AUTOSAR XML (schema 4-0-3)
standard types defined: UInt32, UInt8
package /AUTOSAR_Platform/DataConstrs
  range DC_UInt8: raw 0..255
package /PATAC/Facility/DataTypes/Implementation
  unit NoUnit: factor-si-to-unit=1, offset-si-to-unit=0
package /PATAC/MSM/ComponentTypes
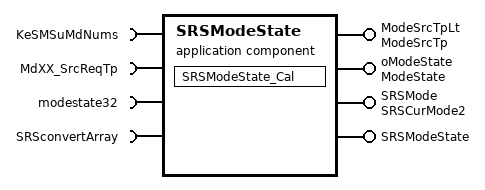
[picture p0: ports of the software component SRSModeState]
  application sw component type SRSModeState
    4 x provide port:
      ModeSrcTpLt: nonqueued-sender-com-spec{data-element=ModeSrcTp/Val, init-value=0}, provided-interface=ModeSrcTp
      oModeState: nonqueued-sender-com-spec=data-element=ModeState/Val, provided-interface=ModeState
      SRSMode: nonqueued-sender-com-spec{data-element=SRSCurMode2/Val, init-value=0}, provided-interface=SRSCurMode2
      SRSModeState: server-com-spec{operation=Cal, queue-length=1}, provided-interface=SRSModeState
    4 x require port:
      KeSMSuMdNums: parameter-require-com-spec{init-value=26, parameter=KeSMSuMdNums/Val}, required-interface=KeSMSuMdNums
      MdXX_SrcReqTp: required-interface=MdXX_SrcReqTp
        required-com-specs:
          data-element=Md1_SrcTp, filter=data-filter-type=ALWAYS, init-value=0
          data-element=Md{10..19}_SrcTp, filter=data-filter-type=ALWAYS, init-value=0
          data-element=Md2_SrcTp, filter=data-filter-type=ALWAYS, init-value=0
          data-element=Md{20..29}_SrcTp, filter=data-filter-type=ALWAYS, init-value=0
          data-element=Md3_SrcTp, filter=data-filter-type=ALWAYS, init-value=0
          data-element=Md{30..32}_SrcTp, filter=data-filter-type=ALWAYS, init-value=0
          data-element=Md{4..9}_SrcTp, filter=data-filter-type=ALWAYS, init-value=0
      modestate32: nonqueued-receiver-com-spec{data-element=modestate32/Val, filter=data-filter-type=ALWAYS, init-value=0}, required-interface=modestate32
      SRSconvertArray: parameter-require-com-spec{init-value=[0, 1, 5, 8, 2, 9, 10, 11, 6, 7, 3, 12, 4, 13, 14, 15, 16, 17, 18, 19, 20, 21, 22, 23, 24, 25, 26, 27, 28, 29, 30, 31], parameter=SRSconvertArray/Val}, required-interface=SRSconvertArray
    behavior SRSModeState_InternalBehavior
      operation invoked event OIT_SRSModeState_Cal_SRSModeState_Cal: start-on-event=SRSModeState_Cal, operation=SRSModeState.Cal
      runnable SRSModeState_Cal
        data-receive-point-by-arguments:
          33 x access:
            REC_MdXX_SrcReqTp_Md1_SrcTp: accessed-variable=MdXX_SrcReqTp.Md1_SrcTp
            REC_MdXX_SrcReqTp_Md{10..19}_SrcTp: accessed-variable=MdXX_SrcReqTp.Md{10..19}_SrcTp
            REC_MdXX_SrcReqTp_Md2_SrcTp: accessed-variable=MdXX_SrcReqTp.Md2_SrcTp
            REC_MdXX_SrcReqTp_Md{20..29}_SrcTp: accessed-variable=MdXX_SrcReqTp.Md{20..29}_SrcTp
            REC_MdXX_SrcReqTp_Md3_SrcTp: accessed-variable=MdXX_SrcReqTp.Md3_SrcTp
            REC_MdXX_SrcReqTp_Md{30..32}_SrcTp: accessed-variable=MdXX_SrcReqTp.Md{30..32}_SrcTp
            REC_MdXX_SrcReqTp_Md{4..9}_SrcTp: accessed-variable=MdXX_SrcReqTp.Md{4..9}_SrcTp
            REC_modestate32_Val: accessed-variable=modestate32.Val
        data-send-points:
          access SEND_ModeSrcTpLt_Val: accessed-variable=ModeSrcTpLt.Val
          access SEND_oModeState_Val: accessed-variable=oModeState.Val
          access SEND_SRSMode_Val: accessed-variable=SRSMode.Val
        parameter access PA_KeSMSuMdNums_Val: accessed-parameter=KeSMSuMdNums.Val
        parameter access PA_SRSconvertArray_Val: accessed-parameter=SRSconvertArray.Val
  swc implementation SRSModeState_Implementation: behavior=SRSModeState_InternalBehavior
    code-descriptors:
      code Default: artifact-descriptors=autosar-engineering-object={short-label=Default, category=SWSRC}
package /PATAC/MSM/ModeAdjust/CalPortInterface
  parameter interface KeSMSuMdNums
    parameter data prototype Val: sw-calibration-access=READ-WRITE, type=UInt8
  parameter interface SRSconvertArray
    parameter data prototype Val: sw-calibration-access=READ-WRITE, type=Array1x32_Uint8
package /PATAC/MSM/ModeAdjust/DataType
  4 x impl type, all with sw-calibration-access=READ-ONLY, type-emitter=RTE:
    Array1x32_Uint8: category=ARRAY
      element Element: array-size=32, array-size-semantics=FIXED-SIZE, implementation-data-type=UInt8
    MdTp1: category=VALUE, base-type=UInt8, compu {0=MdTp_None, 1=MdTp_EzeEntry, 2=MdTp_EzeExt, 3=MdTp_Vip, 4=MdTp_Lug, 5=MdTp_Recovery, 6=MdTp_Intimacy, 7=MdTp_Family, 8=MdTp_Lying, 9=MdTp_LgrstOpenLt, 10=MdTp_LgrstCloseLt, 11=MdTp_LgrstOpenRt, 12=MdTp_LgrstCloseRt}
    SrcReqTp1: category=VALUE, base-type=UInt8, compu {0=SrcReqTp_None, 1=SrcReqTp_Local, 2=SrcReqTp_HMI2L, 3=SrcReqTp_HMI2R, 4=SrcReqTp_HMI, 5=SrcReqTp_Remote, 6=SrcReqTp_SRS}
    SRSCurMode2:
      category=VALUE
      base-type=UInt8
      compu {0=SRSMode_None, 1=SRSMode_EZEEntry, 2=SRSMode_EzeExt, 3=SRSMode_LfVip, 4=SRSMode_RtVip, 5=SRSMode_AllVip, 6=SRSMode_LfLug, 7=SRSMode_RtLug, 8=SRSMode_AllLug, 9=SRSMode_IntimacyL, 10=SRSMode_FamilyR, 11=SRSMode_FamilyL, 12=SRSMode_RcvyL, 13=SRSMode_RcvyR, 14=SRSMode_LyingL, 15=SRSMode_LyingR, 16=SRSMode_LgrstOpenLt, 17=SRSMode_LgrstCloseLt, 18=SRSMode_LgrstOpenRt, 19=SRSMode_LgrstCloseRt, 20=SRSMode_IntimacyR, 21=SRSMode_EzeEntry4s2L, 22=SRSMode_EzeExt4s2L, 23=SRSMode_EzeEntry4s2R, 24=SRSMode_EzeExt4s2R, 25=SRSMode_EzeEntryAll4sBwd, 26=SRSMode_EzeEntryAll4sFwd}
package /PATAC/MSM/ModeAdjust/PortInterface
  client server interface SRSModeState
    operation Cal
  5 x sender receiver interface:
    MdXX_SrcReqTp
      32 x data, all with type=SrcReqTp1:
        Md1_SrcTp
        Md{10..19}_SrcTp
        Md2_SrcTp
        Md{20..29}_SrcTp
        Md3_SrcTp
        Md{30..32}_SrcTp
        Md{4..9}_SrcTp
      invalidation-policys:
        data-element=Md1_SrcTp, handle-invalid=DONT-INVALIDATE
        data-element=Md2_SrcTp, handle-invalid=DONT-INVALIDATE
        data-element=Md4_SrcTp, handle-invalid=DONT-INVALIDATE
        data-element=Md3_SrcTp, handle-invalid=DONT-INVALIDATE
        data-element=Md6_SrcTp, handle-invalid=DONT-INVALIDATE
        data-element=Md5_SrcTp, handle-invalid=DONT-INVALIDATE
        data-element=Md10_SrcTp, handle-invalid=DONT-INVALIDATE
        data-element=Md7_SrcTp, handle-invalid=DONT-INVALIDATE
        data-element=Md12_SrcTp, handle-invalid=DONT-INVALIDATE
        data-element=Md8_SrcTp, handle-invalid=DONT-INVALIDATE
        data-element=Md11_SrcTp, handle-invalid=DONT-INVALIDATE
        data-element=Md9_SrcTp, handle-invalid=DONT-INVALIDATE
        data-element=Md14_SrcTp, handle-invalid=DONT-INVALIDATE
        data-element=Md13_SrcTp, handle-invalid=DONT-INVALIDATE
        data-element=Md17_SrcTp, handle-invalid=DONT-INVALIDATE
        data-element=Md16_SrcTp, handle-invalid=DONT-INVALIDATE
        data-element=Md15_SrcTp, handle-invalid=DONT-INVALIDATE
        data-element=Md19_SrcTp, handle-invalid=DONT-INVALIDATE
        data-element=Md18_SrcTp, handle-invalid=DONT-INVALIDATE
        data-element=Md{20..22}_SrcTp, handle-invalid=DONT-INVALIDATE
        data-element=Md24_SrcTp, handle-invalid=DONT-INVALIDATE
        data-element=Md23_SrcTp, handle-invalid=DONT-INVALIDATE
        data-element=Md26_SrcTp, handle-invalid=DONT-INVALIDATE
        data-element=Md25_SrcTp, handle-invalid=DONT-INVALIDATE
        data-element=Md28_SrcTp, handle-invalid=DONT-INVALIDATE
        data-element=Md27_SrcTp, handle-invalid=DONT-INVALIDATE
        data-element=Md30_SrcTp, handle-invalid=DONT-INVALIDATE
        data-element=Md29_SrcTp, handle-invalid=DONT-INVALIDATE
        data-element=Md32_SrcTp, handle-invalid=DONT-INVALIDATE
        data-element=Md31_SrcTp, handle-invalid=DONT-INVALIDATE
    ModeSrcTp: invalidation-policy{data-element=ModeSrcTp/Val, handle-invalid=DONT-INVALIDATE}
      data Val: type=SrcReqTp1
    ModeState: invalidation-policy{data-element=ModeState/Val, handle-invalid=DONT-INVALIDATE}
      data Val: type=MdTp1
    modestate32: invalidation-policy{data-element=modestate32/Val, handle-invalid=DONT-INVALIDATE}
      data Val: type=UInt32
    SRSCurMode2: invalidation-policy{data-element=SRSCurMode2/Val, handle-invalid=DONT-INVALIDATE}
      data Val: type=SRSCurMode2
